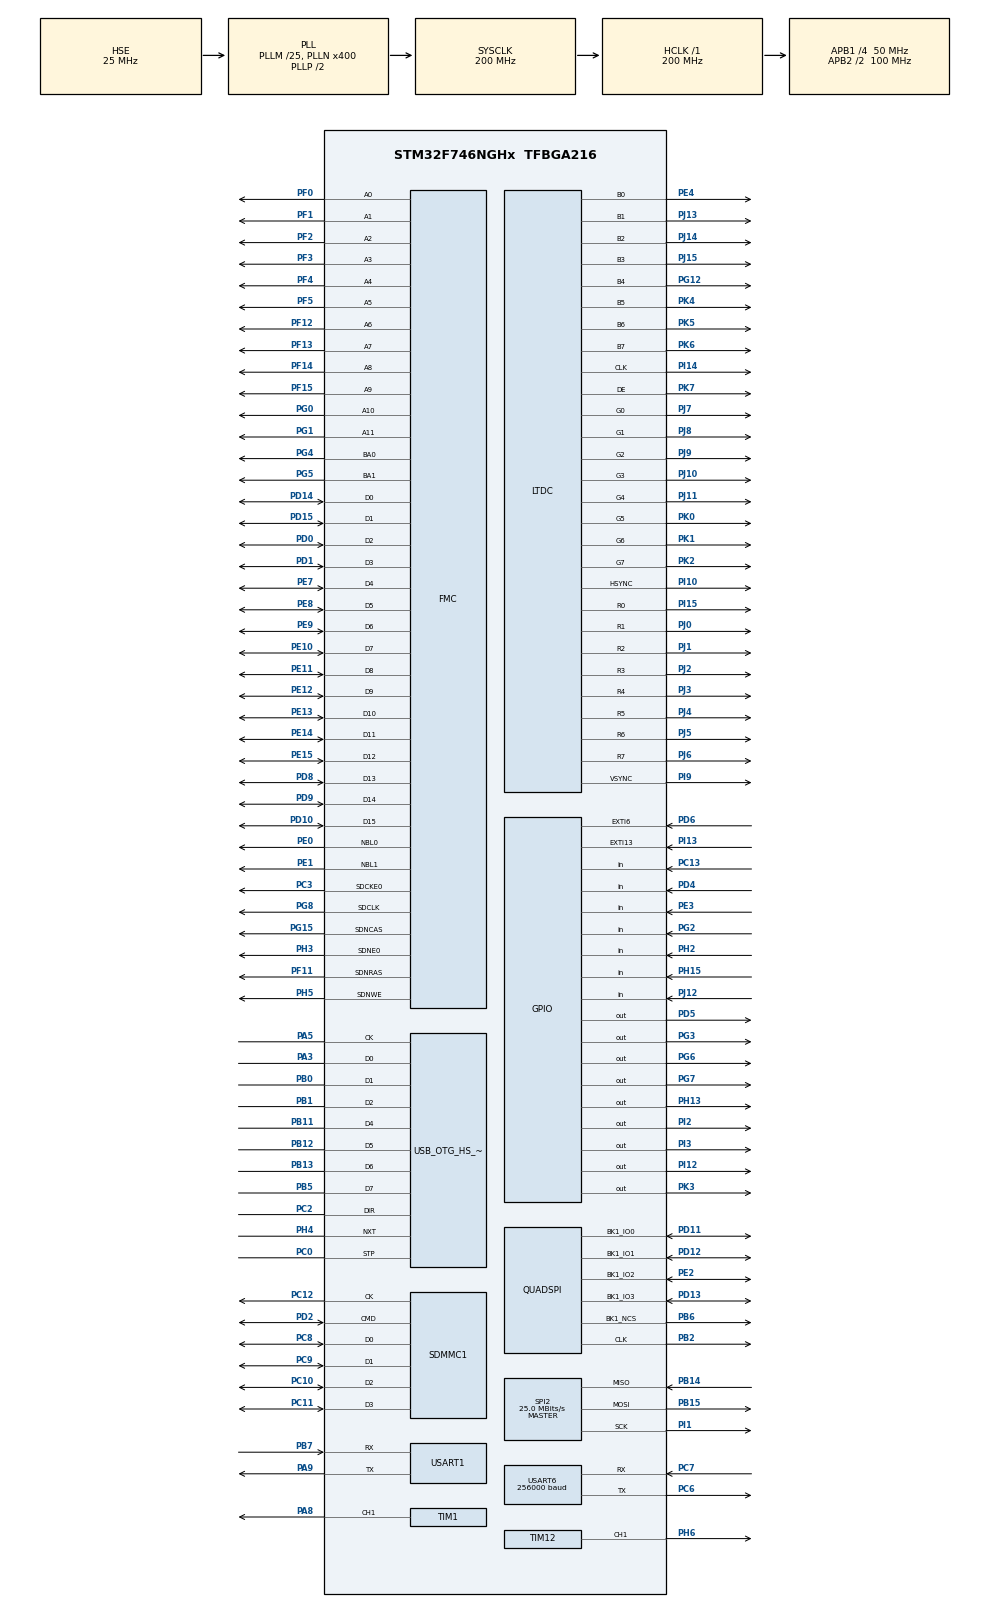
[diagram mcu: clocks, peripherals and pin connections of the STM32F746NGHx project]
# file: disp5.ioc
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Dma.MEMTOMEM.2.Direction=DMA_MEMORY_TO_MEMORY
Dma.MEMTOMEM.2.FIFOMode=DMA_FIFOMODE_ENABLE
Dma.MEMTOMEM.2.FIFOThreshold=DMA_FIFO_THRESHOLD_FULL
Dma.MEMTOMEM.2.Instance=DMA2_Stream0
Dma.MEMTOMEM.2.MemBurst=DMA_MBURST_SINGLE
Dma.MEMTOMEM.2.MemDataAlignment=DMA_MDATAALIGN_BYTE
Dma.MEMTOMEM.2.MemInc=DMA_MINC_ENABLE
Dma.MEMTOMEM.2.Mode=DMA_NORMAL
Dma.MEMTOMEM.2.PeriphBurst=DMA_PBURST_SINGLE
Dma.MEMTOMEM.2.PeriphDataAlignment=DMA_PDATAALIGN_BYTE
Dma.MEMTOMEM.2.PeriphInc=DMA_PINC_ENABLE
Dma.MEMTOMEM.2.Priority=DMA_PRIORITY_HIGH
Dma.Request0=USART6_RX
Dma.Request1=USART6_TX
Dma.Request2=MEMTOMEM
Dma.USART6_RX.0.Direction=DMA_PERIPH_TO_MEMORY
Dma.USART6_RX.0.FIFOMode=DMA_FIFOMODE_DISABLE
Dma.USART6_RX.0.Instance=DMA2_Stream1
Dma.USART6_RX.0.MemDataAlignment=DMA_MDATAALIGN_BYTE
Dma.USART6_RX.0.MemInc=DMA_MINC_ENABLE
Dma.USART6_RX.0.Mode=DMA_NORMAL
Dma.USART6_RX.0.PeriphDataAlignment=DMA_PDATAALIGN_BYTE
Dma.USART6_RX.0.PeriphInc=DMA_PINC_DISABLE
Dma.USART6_RX.0.Priority=DMA_PRIORITY_VERY_HIGH
Dma.USART6_TX.1.Direction=DMA_MEMORY_TO_PERIPH
Dma.USART6_TX.1.FIFOMode=DMA_FIFOMODE_DISABLE
Dma.USART6_TX.1.Instance=DMA2_Stream6
Dma.USART6_TX.1.MemDataAlignment=DMA_MDATAALIGN_BYTE
Dma.USART6_TX.1.MemInc=DMA_MINC_ENABLE
Dma.USART6_TX.1.Mode=DMA_NORMAL
Dma.USART6_TX.1.PeriphDataAlignment=DMA_PDATAALIGN_BYTE
Dma.USART6_TX.1.PeriphInc=DMA_PINC_DISABLE
Dma.USART6_TX.1.Priority=DMA_PRIORITY_VERY_HIGH
FMC.CASLatency1=FMC_SDRAM_CAS_LATENCY_3
FMC.ExitSelfRefreshDelay1=7
FMC.LoadToActiveDelay1=2
FMC.RCDDelay1=2
FMC.RPDelay1=2
FMC.RPDelay2=2
FMC.ReadBurst1=FMC_SDRAM_RBURST_ENABLE
FMC.ReadBurst2=FMC_SDRAM_RBURST_ENABLE
FMC.RowCycleDelay1=7
FMC.RowCycleDelay2=7
FMC.SDClockPeriod1=FMC_SDRAM_CLOCK_PERIOD_2
FMC.SDClockPeriod2=FMC_SDRAM_CLOCK_PERIOD_2
FMC.SelfRefreshTime1=4
FMC.WriteRecoveryTime1=3
LTDC.ActiveH=272
LTDC.ActiveW=480
LTDC.Alpha_L0=255
LTDC.BlendingFactor1_L0=LTDC_BLENDING_FACTOR1_CA
LTDC.BlendingFactor2_L0=LTDC_BLENDING_FACTOR2_CA
LTDC.FBStartAdress_L0=0xC0400000
LTDC.HBP=13
LTDC.HFP=32
LTDC.HSync=41
LTDC.ImageHeight_L0=272
LTDC.ImageWidth_L0=480
LTDC.Layers=1
LTDC.PixelFormat_L0=LTDC_PIXEL_FORMAT_ARGB8888
LTDC.VSync=10
LTDC.WindowX1_L0=480
LTDC.WindowY1_L0=272
Mcu.Family=STM32F7
Mcu.Name=STM32F746NGHx
Mcu.Package=TFBGA216
NVIC.DMA2D_IRQn=true\:0\:0\:false\:false\:true\:true\:true
NVIC.DMA2_Stream1_IRQn=true\:0\:0\:false\:false\:true\:false\:true
NVIC.DMA2_Stream6_IRQn=true\:0\:0\:false\:false\:true\:false\:true
NVIC.LTDC_IRQn=true\:0\:0\:false\:false\:true\:true\:true
NVIC.PriorityGroup=NVIC_PRIORITYGROUP_4
NVIC.TIM6_DAC_IRQn=true\:0\:0\:false\:false\:true\:false\:true
NVIC.TimeBase=TIM6_DAC_IRQn
NVIC.TimeBaseIP=TIM6
NVIC.USART6_IRQn=true\:0\:0\:false\:false\:true\:true\:true
PA0/WKUP.GPIO_Mode=GPIO_MODE_ANALOG
PA0/WKUP.GPIO_PuPd=GPIO_NOPULL
PA0/WKUP.Signal=ADCx_IN0
PA1.GPIO_Mode=GPIO_MODE_AF_PP
PA1.GPIO_PuPd=GPIO_NOPULL
PA1.GPIO_Speed=GPIO_SPEED_FREQ_VERY_HIGH
PA1.Signal=ETH_REF_CLK
PA10.GPIO_Mode=GPIO_MODE_AF_PP
PA10.GPIO_PuPd=GPIO_NOPULL
PA10.GPIO_Speed=GPIO_SPEED_FREQ_VERY_HIGH
PA10.Signal=USB_OTG_FS_ID
PA11.GPIO_Mode=GPIO_MODE_AF_PP
PA11.GPIO_PuPd=GPIO_NOPULL
PA11.GPIO_Speed=GPIO_SPEED_FREQ_VERY_HIGH
PA11.Signal=USB_OTG_FS_DM
PA12.GPIO_Mode=GPIO_MODE_AF_PP
PA12.GPIO_PuPd=GPIO_NOPULL
PA12.GPIO_Speed=GPIO_SPEED_FREQ_VERY_HIGH
PA12.Signal=USB_OTG_FS_DP
PA13.Mode=Serial_Wire
PA13.Signal=SYS_JTMS-SWDIO
PA14.Mode=Serial_Wire
PA14.Signal=SYS_JTCK-SWCLK
PA15.GPIO_ModeDefaultPP=GPIO_MODE_AF_PP
PA15.GPIO_PuPd=GPIO_NOPULL
PA15.GPIO_Speed=GPIO_SPEED_FREQ_LOW
PA15.Signal=S_TIM2_CH1_ETR
PA2.GPIO_Mode=GPIO_MODE_AF_PP
PA2.GPIO_PuPd=GPIO_NOPULL
PA2.GPIO_Speed=GPIO_SPEED_FREQ_VERY_HIGH
PA2.Signal=ETH_MDIO
PA3.GPIO_Mode=GPIO_MODE_AF_PP
PA3.GPIO_PuPd=GPIO_NOPULL
PA3.GPIO_Speed=GPIO_SPEED_FREQ_VERY_HIGH
PA3.Mode=Host_HS
PA3.Signal=USB_OTG_HS_ULPI_D0
PA4.GPIO_Mode=GPIO_MODE_AF_PP
PA4.GPIO_PuPd=GPIO_NOPULL
PA4.GPIO_Speed=GPIO_SPEED_FREQ_LOW
PA4.Signal=DCMI_HSYNC
PA5.GPIO_Mode=GPIO_MODE_AF_PP
PA5.GPIO_PuPd=GPIO_NOPULL
PA5.GPIO_Speed=GPIO_SPEED_FREQ_VERY_HIGH
PA5.Mode=Host_HS
PA5.Signal=USB_OTG_HS_ULPI_CK
PA6.Signal=DCMI_PIXCLK
PA7.GPIO_Mode=GPIO_MODE_AF_PP
PA7.GPIO_PuPd=GPIO_NOPULL
PA7.GPIO_Speed=GPIO_SPEED_FREQ_VERY_HIGH
PA7.Signal=ETH_CRS_DV
PA8.GPIO_ModeDefaultPP=GPIO_MODE_AF_PP
PA8.GPIO_PuPd=GPIO_NOPULL
PA8.GPIO_Speed=GPIO_SPEED_FREQ_LOW
PA8.Signal=S_TIM1_CH1
PA9.GPIO_Mode=GPIO_MODE_AF_PP
PA9.GPIO_ModeDefaultPP=GPIO_MODE_AF_PP
PA9.GPIO_PuPd=GPIO_NOPULL
PA9.GPIO_Speed=GPIO_SPEED_FREQ_VERY_HIGH
PA9.Mode=Asynchronous
PA9.Signal=USART1_TX
PB0.GPIO_Mode=GPIO_MODE_AF_PP
PB0.GPIO_PuPd=GPIO_NOPULL
PB0.GPIO_Speed=GPIO_SPEED_FREQ_VERY_HIGH
PB0.Mode=Host_HS
PB0.Signal=USB_OTG_HS_ULPI_D1
PB1.GPIO_Mode=GPIO_MODE_AF_PP
PB1.GPIO_PuPd=GPIO_NOPULL
PB1.GPIO_Speed=GPIO_SPEED_FREQ_VERY_HIGH
PB1.Mode=Host_HS
PB1.Signal=USB_OTG_HS_ULPI_D2
PB10.GPIO_Mode=GPIO_MODE_AF_PP
PB10.GPIO_PuPd=GPIO_NOPULL
PB10.GPIO_Speed=GPIO_SPEED_FREQ_VERY_HIGH
PB10.Signal=USB_OTG_HS_ULPI_D3
PB11.GPIO_Mode=GPIO_MODE_AF_PP
PB11.GPIO_PuPd=GPIO_NOPULL
PB11.GPIO_Speed=GPIO_SPEED_FREQ_VERY_HIGH
PB11.Mode=Host_HS
PB11.Signal=USB_OTG_HS_ULPI_D4
PB12.GPIO_Mode=GPIO_MODE_AF_PP
PB12.GPIO_PuPd=GPIO_NOPULL
PB12.GPIO_Speed=GPIO_SPEED_FREQ_VERY_HIGH
PB12.Mode=Host_HS
PB12.Signal=USB_OTG_HS_ULPI_D5
PB13.GPIO_Mode=GPIO_MODE_AF_PP
PB13.GPIO_PuPd=GPIO_NOPULL
PB13.GPIO_Speed=GPIO_SPEED_FREQ_VERY_HIGH
PB13.Mode=Host_HS
PB13.Signal=USB_OTG_HS_ULPI_D6
PB14.GPIO_Mode=GPIO_MODE_AF_PP
PB14.GPIO_PuPd=GPIO_NOPULL
PB14.GPIO_Speed=GPIO_SPEED_FREQ_VERY_HIGH
PB14.Mode=Full_Duplex_Master
PB14.Signal=SPI2_MISO
PB15.GPIO_Mode=GPIO_MODE_AF_PP
PB15.GPIO_PuPd=GPIO_NOPULL
PB15.GPIO_Speed=GPIO_SPEED_FREQ_VERY_HIGH
PB15.Mode=Full_Duplex_Master
PB15.Signal=SPI2_MOSI
PB2.Mode=Single Bank 1
PB2.Signal=QUADSPI_CLK
PB3.Signal=SYS_JTDO-SWO
PB4.GPIO_ModeDefaultPP=GPIO_MODE_AF_PP
PB4.GPIO_PuPd=GPIO_NOPULL
PB4.GPIO_Speed=GPIO_SPEED_FREQ_LOW
PB4.Signal=S_TIM3_CH1
PB5.GPIO_Mode=GPIO_MODE_AF_PP
PB5.GPIO_PuPd=GPIO_NOPULL
PB5.GPIO_Speed=GPIO_SPEED_FREQ_VERY_HIGH
PB5.Mode=Host_HS
PB5.Signal=USB_OTG_HS_ULPI_D7
PB6.GPIO_Mode=GPIO_MODE_AF_PP
PB6.GPIO_PuPd=GPIO_NOPULL
PB6.GPIO_Speed=GPIO_SPEED_FREQ_VERY_HIGH
PB6.Mode=Single Bank 1
PB6.Signal=QUADSPI_BK1_NCS
PB7.GPIO_Mode=GPIO_MODE_AF_PP
PB7.GPIO_ModeDefaultPP=GPIO_MODE_AF_PP
PB7.GPIO_PuPd=GPIO_NOPULL
PB7.GPIO_Speed=GPIO_SPEED_FREQ_VERY_HIGH
PB7.Mode=Asynchronous
PB7.Signal=USART1_RX
PB8.GPIO_Mode=GPIO_MODE_AF_OD
PB8.GPIO_PuPd=GPIO_NOPULL
PB8.GPIO_PuPdOD=GPIO_PULLUP
PB8.GPIO_Speed=GPIO_SPEED_FREQ_VERY_HIGH
PB8.Signal=I2C1_SCL
PB9.GPIO_Mode=GPIO_MODE_AF_OD
PB9.GPIO_PuPd=GPIO_NOPULL
PB9.GPIO_PuPdOD=GPIO_PULLUP
PB9.GPIO_Speed=GPIO_SPEED_FREQ_VERY_HIGH
PB9.Signal=I2C1_SDA
PC0.GPIO_Mode=GPIO_MODE_AF_PP
PC0.GPIO_PuPd=GPIO_NOPULL
PC0.GPIO_Speed=GPIO_SPEED_FREQ_VERY_HIGH
PC0.Mode=Host_HS
PC0.Signal=USB_OTG_HS_ULPI_STP
PC1.GPIO_Mode=GPIO_MODE_AF_PP
PC1.GPIO_PuPd=GPIO_NOPULL
PC1.GPIO_Speed=GPIO_SPEED_FREQ_VERY_HIGH
PC1.Signal=ETH_MDC
PC10.GPIO_Mode=GPIO_MODE_AF_PP
PC10.GPIO_PuPd=GPIO_NOPULL
PC10.GPIO_Speed_High_Default=GPIO_SPEED_FREQ_VERY_HIGH
PC10.Mode=SD_4_bits_Wide_bus
PC10.Signal=SDMMC1_D2
PC11.GPIO_Mode=GPIO_MODE_AF_PP
PC11.GPIO_PuPd=GPIO_NOPULL
PC11.GPIO_Speed_High_Default=GPIO_SPEED_FREQ_VERY_HIGH
PC11.Mode=SD_4_bits_Wide_bus
PC11.Signal=SDMMC1_D3
PC12.GPIO_Mode=GPIO_MODE_AF_PP
PC12.GPIO_PuPd=GPIO_NOPULL
PC12.GPIO_Speed_High_Default=GPIO_SPEED_FREQ_VERY_HIGH
PC12.Mode=SD_4_bits_Wide_bus
PC12.Signal=SDMMC1_CK
PC13.GPIO_Mode=GPIO_MODE_INPUT
PC13.GPIO_PuPd=GPIO_NOPULL
PC13.Signal=GPIO_Input
PC14/OSC32_IN.Mode=LSE-External-Oscillator
PC14/OSC32_IN.Signal=RCC_OSC32_IN
PC15/OSC32_OUT.Mode=LSE-External-Oscillator
PC15/OSC32_OUT.Signal=RCC_OSC32_OUT
PC2.GPIO_Mode=GPIO_MODE_AF_PP
PC2.GPIO_PuPd=GPIO_NOPULL
PC2.GPIO_Speed=GPIO_SPEED_FREQ_VERY_HIGH
PC2.Mode=Host_HS
PC2.Signal=USB_OTG_HS_ULPI_DIR
PC3.GPIO_Mode=GPIO_MODE_AF_PP
PC3.GPIO_PuPd=GPIO_NOPULL
PC3.GPIO_Speed_High_Default=GPIO_SPEED_FREQ_VERY_HIGH
PC3.Mode=SdramChipSelect1_1
PC3.Signal=FMC_SDCKE0
PC4.GPIO_Mode=GPIO_MODE_AF_PP
PC4.GPIO_PuPd=GPIO_NOPULL
PC4.GPIO_Speed=GPIO_SPEED_FREQ_VERY_HIGH
PC4.Signal=ETH_RXD0
PC5.GPIO_Mode=GPIO_MODE_AF_PP
PC5.GPIO_PuPd=GPIO_NOPULL
PC5.GPIO_Speed=GPIO_SPEED_FREQ_VERY_HIGH
PC5.Signal=ETH_RXD1
PC6.GPIO_ModeDefaultPP=GPIO_MODE_AF_PP
PC6.GPIO_PuPd=GPIO_NOPULL
PC6.GPIO_Speed=GPIO_SPEED_FREQ_VERY_HIGH
PC6.Mode=Asynchronous
PC6.Signal=USART6_TX
PC7.GPIO_ModeDefaultPP=GPIO_MODE_AF_PP
PC7.GPIO_PuPd=GPIO_NOPULL
PC7.GPIO_Speed=GPIO_SPEED_FREQ_VERY_HIGH
PC7.Mode=Asynchronous
PC7.Signal=USART6_RX
PC8.Mode=SD_4_bits_Wide_bus
PC8.Signal=SDMMC1_D0
PC9.Mode=SD_4_bits_Wide_bus
PC9.Signal=SDMMC1_D1
PD0.GPIO_Mode=GPIO_MODE_AF_PP
PD0.GPIO_PuPd=GPIO_NOPULL
PD0.GPIO_Speed_High_Default=GPIO_SPEED_FREQ_VERY_HIGH
PD0.Signal=FMC_D2_DA2
PD1.GPIO_Mode=GPIO_MODE_AF_PP
PD1.GPIO_PuPd=GPIO_NOPULL
PD1.GPIO_Speed_High_Default=GPIO_SPEED_FREQ_VERY_HIGH
PD1.Signal=FMC_D3_DA3
PD10.GPIO_Mode=GPIO_MODE_AF_PP
PD10.GPIO_PuPd=GPIO_NOPULL
PD10.GPIO_Speed_High_Default=GPIO_SPEED_FREQ_VERY_HIGH
PD10.Signal=FMC_D15_DA15
PD11.GPIO_Mode=GPIO_MODE_AF_PP
PD11.GPIO_PuPd=GPIO_NOPULL
PD11.GPIO_Speed=GPIO_SPEED_FREQ_VERY_HIGH
PD11.Mode=Single Bank 1
PD11.Signal=QUADSPI_BK1_IO0
PD12.GPIO_Mode=GPIO_MODE_AF_PP
PD12.GPIO_PuPd=GPIO_NOPULL
PD12.GPIO_Speed=GPIO_SPEED_FREQ_VERY_HIGH
PD12.Mode=Single Bank 1
PD12.Signal=QUADSPI_BK1_IO1
PD13.GPIO_Mode=GPIO_MODE_AF_PP
PD13.GPIO_PuPd=GPIO_NOPULL
PD13.GPIO_Speed=GPIO_SPEED_FREQ_VERY_HIGH
PD13.Mode=Single Bank 1
PD13.Signal=QUADSPI_BK1_IO3
PD14.GPIO_Mode=GPIO_MODE_AF_PP
PD14.GPIO_PuPd=GPIO_NOPULL
PD14.GPIO_Speed_High_Default=GPIO_SPEED_FREQ_VERY_HIGH
PD14.Signal=FMC_D0_DA0
PD15.GPIO_Mode=GPIO_MODE_AF_PP
PD15.GPIO_PuPd=GPIO_NOPULL
PD15.GPIO_Speed_High_Default=GPIO_SPEED_FREQ_VERY_HIGH
PD15.Signal=FMC_D1_DA1
PD2.GPIO_Mode=GPIO_MODE_AF_PP
PD2.GPIO_PuPd=GPIO_NOPULL
PD2.GPIO_Speed_High_Default=GPIO_SPEED_FREQ_VERY_HIGH
PD2.Mode=SD_4_bits_Wide_bus
PD2.Signal=SDMMC1_CMD
PD3.GPIO_Mode=GPIO_MODE_AF_PP
PD3.GPIO_PuPd=GPIO_NOPULL
PD3.GPIO_Speed=GPIO_SPEED_FREQ_LOW
PD3.Signal=DCMI_D5
PD4.GPIO_Mode=GPIO_MODE_INPUT
PD4.GPIO_PuPd=GPIO_NOPULL
PD4.Signal=GPIO_Input
PD5.GPIO_ModeDefaultOutputPP=GPIO_MODE_OUTPUT_PP
PD5.GPIO_PuPd=GPIO_NOPULL
PD5.GPIO_Speed=GPIO_SPEED_FREQ_LOW
PD5.PinState=GPIO_PIN_RESET
PD5.Signal=GPIO_Output
PD6.GPIO_ModeDefaultEXTI=GPIO_MODE_IT_RISING
PD6.GPIO_PuPd=GPIO_NOPULL
PD6.Signal=GPXTI6
PD7.GPIO_Mode=GPIO_MODE_AF_PP
PD7.GPIO_PuPd=GPIO_NOPULL
PD7.GPIO_Speed=GPIO_SPEED_FREQ_LOW
PD7.Signal=SPDIFRX_IN0
PD8.GPIO_Mode=GPIO_MODE_AF_PP
PD8.GPIO_PuPd=GPIO_NOPULL
PD8.GPIO_Speed_High_Default=GPIO_SPEED_FREQ_VERY_HIGH
PD8.Signal=FMC_D13_DA13
PD9.GPIO_Mode=GPIO_MODE_AF_PP
PD9.GPIO_PuPd=GPIO_NOPULL
PD9.GPIO_Speed_High_Default=GPIO_SPEED_FREQ_VERY_HIGH
PD9.Signal=FMC_D14_DA14
PE0.GPIO_Mode=GPIO_MODE_AF_PP
PE0.GPIO_PuPd=GPIO_NOPULL
PE0.GPIO_Speed_High_Default=GPIO_SPEED_FREQ_VERY_HIGH
PE0.Signal=FMC_NBL0
PE1.GPIO_Mode=GPIO_MODE_AF_PP
PE1.GPIO_PuPd=GPIO_NOPULL
PE1.GPIO_Speed_High_Default=GPIO_SPEED_FREQ_VERY_HIGH
PE1.Signal=FMC_NBL1
PE10.GPIO_Mode=GPIO_MODE_AF_PP
PE10.GPIO_PuPd=GPIO_NOPULL
PE10.GPIO_Speed_High_Default=GPIO_SPEED_FREQ_VERY_HIGH
PE10.Signal=FMC_D7_DA7
PE11.GPIO_Mode=GPIO_MODE_AF_PP
PE11.GPIO_PuPd=GPIO_NOPULL
PE11.GPIO_Speed_High_Default=GPIO_SPEED_FREQ_VERY_HIGH
PE11.Signal=FMC_D8_DA8
PE12.GPIO_Mode=GPIO_MODE_AF_PP
PE12.GPIO_PuPd=GPIO_NOPULL
PE12.GPIO_Speed_High_Default=GPIO_SPEED_FREQ_VERY_HIGH
PE12.Signal=FMC_D9_DA9
PE13.GPIO_Mode=GPIO_MODE_AF_PP
PE13.GPIO_PuPd=GPIO_NOPULL
PE13.GPIO_Speed_High_Default=GPIO_SPEED_FREQ_VERY_HIGH
PE13.Signal=FMC_D10_DA10
PE14.GPIO_Mode=GPIO_MODE_AF_PP
PE14.GPIO_PuPd=GPIO_NOPULL
PE14.GPIO_Speed_High_Default=GPIO_SPEED_FREQ_VERY_HIGH
PE14.Signal=FMC_D11_DA11
PE15.GPIO_Mode=GPIO_MODE_AF_PP
PE15.GPIO_PuPd=GPIO_NOPULL
PE15.GPIO_Speed_High_Default=GPIO_SPEED_FREQ_VERY_HIGH
PE15.Signal=FMC_D12_DA12
PE2.GPIO_Mode=GPIO_MODE_AF_PP
PE2.GPIO_PuPd=GPIO_NOPULL
PE2.GPIO_Speed=GPIO_SPEED_FREQ_VERY_HIGH
PE2.Mode=Single Bank 1
PE2.Signal=QUADSPI_BK1_IO2
PE3.GPIO_Mode=GPIO_MODE_INPUT
PE3.GPIO_PuPd=GPIO_NOPULL
PE3.Signal=GPIO_Input
PE4.GPIO_Mode=GPIO_MODE_AF_PP
PE4.GPIO_PuPd=GPIO_NOPULL
PE4.GPIO_Speed=GPIO_SPEED_FREQ_LOW
PE4.Mode=RGB888
PE4.Signal=LTDC_B0
PE5.GPIO_Mode=GPIO_MODE_AF_PP
PE5.GPIO_PuPd=GPIO_NOPULL
PE5.GPIO_Speed=GPIO_SPEED_FREQ_LOW
PE5.Signal=DCMI_D6
PE6.GPIO_Mode=GPIO_MODE_AF_PP
PE6.GPIO_PuPd=GPIO_NOPULL
PE6.GPIO_Speed=GPIO_SPEED_FREQ_LOW
PE6.Signal=DCMI_D7
PE7.GPIO_Mode=GPIO_MODE_AF_PP
PE7.GPIO_PuPd=GPIO_NOPULL
PE7.GPIO_Speed_High_Default=GPIO_SPEED_FREQ_VERY_HIGH
PE7.Signal=FMC_D4_DA4
PE8.GPIO_Mode=GPIO_MODE_AF_PP
PE8.GPIO_PuPd=GPIO_NOPULL
PE8.GPIO_Speed_High_Default=GPIO_SPEED_FREQ_VERY_HIGH
PE8.Signal=FMC_D5_DA5
PE9.GPIO_Mode=GPIO_MODE_AF_PP
PE9.GPIO_PuPd=GPIO_NOPULL
PE9.GPIO_Speed_High_Default=GPIO_SPEED_FREQ_VERY_HIGH
PE9.Signal=FMC_D6_DA6
PF0.GPIO_Mode=GPIO_MODE_AF_PP
PF0.GPIO_PuPd=GPIO_NOPULL
PF0.GPIO_Speed_High_Default=GPIO_SPEED_FREQ_VERY_HIGH
PF0.Signal=FMC_A0
PF1.GPIO_Mode=GPIO_MODE_AF_PP
PF1.GPIO_PuPd=GPIO_NOPULL
PF1.GPIO_Speed_High_Default=GPIO_SPEED_FREQ_VERY_HIGH
PF1.Signal=FMC_A1
PF10.GPIO_Mode=GPIO_MODE_ANALOG
PF10.GPIO_PuPd=GPIO_NOPULL
PF10.Signal=ADC3_IN8
PF11.GPIO_Mode=GPIO_MODE_AF_PP
PF11.GPIO_PuPd=GPIO_NOPULL
PF11.GPIO_Speed_High_Default=GPIO_SPEED_FREQ_VERY_HIGH
PF11.Signal=FMC_SDNRAS
PF12.GPIO_Mode=GPIO_MODE_AF_PP
PF12.GPIO_PuPd=GPIO_NOPULL
PF12.GPIO_Speed_High_Default=GPIO_SPEED_FREQ_VERY_HIGH
PF12.Signal=FMC_A6
PF13.GPIO_Mode=GPIO_MODE_AF_PP
PF13.GPIO_PuPd=GPIO_NOPULL
PF13.GPIO_Speed_High_Default=GPIO_SPEED_FREQ_VERY_HIGH
PF13.Signal=FMC_A7
PF14.GPIO_Mode=GPIO_MODE_AF_PP
PF14.GPIO_PuPd=GPIO_NOPULL
PF14.GPIO_Speed_High_Default=GPIO_SPEED_FREQ_VERY_HIGH
PF14.Signal=FMC_A8
PF15.GPIO_Mode=GPIO_MODE_AF_PP
PF15.GPIO_PuPd=GPIO_NOPULL
PF15.GPIO_Speed_High_Default=GPIO_SPEED_FREQ_VERY_HIGH
PF15.Signal=FMC_A9
PF2.GPIO_Mode=GPIO_MODE_AF_PP
PF2.GPIO_PuPd=GPIO_NOPULL
PF2.GPIO_Speed_High_Default=GPIO_SPEED_FREQ_VERY_HIGH
PF2.Signal=FMC_A2
PF3.GPIO_Mode=GPIO_MODE_AF_PP
PF3.GPIO_PuPd=GPIO_NOPULL
PF3.GPIO_Speed_High_Default=GPIO_SPEED_FREQ_VERY_HIGH
PF3.Signal=FMC_A3
PF4.GPIO_Mode=GPIO_MODE_AF_PP
PF4.GPIO_PuPd=GPIO_NOPULL
PF4.GPIO_Speed_High_Default=GPIO_SPEED_FREQ_VERY_HIGH
PF4.Signal=FMC_A4
PF5.GPIO_Mode=GPIO_MODE_AF_PP
PF5.GPIO_PuPd=GPIO_NOPULL
PF5.GPIO_Speed_High_Default=GPIO_SPEED_FREQ_VERY_HIGH
PF5.Signal=FMC_A5
PF6.GPIO_Mode=GPIO_MODE_ANALOG
PF6.GPIO_PuPd=GPIO_NOPULL
PF6.Signal=ADC3_IN4
PF7.GPIO_Mode=GPIO_MODE_ANALOG
PF7.GPIO_PuPd=GPIO_NOPULL
PF7.Signal=ADC3_IN5
PF8.GPIO_Mode=GPIO_MODE_ANALOG
PF8.GPIO_PuPd=GPIO_NOPULL
PF8.Signal=ADC3_IN6
PF9.GPIO_Mode=GPIO_MODE_ANALOG
PF9.GPIO_PuPd=GPIO_NOPULL
PF9.Signal=ADC3_IN7
PG0.GPIO_Mode=GPIO_MODE_AF_PP
PG0.GPIO_PuPd=GPIO_NOPULL
PG0.GPIO_Speed_High_Default=GPIO_SPEED_FREQ_VERY_HIGH
PG0.Signal=FMC_A10
PG1.GPIO_Mode=GPIO_MODE_AF_PP
PG1.GPIO_PuPd=GPIO_NOPULL
PG1.GPIO_Speed_High_Default=GPIO_SPEED_FREQ_VERY_HIGH
PG1.Signal=FMC_A11
PG10.GPIO_Mode=GPIO_MODE_AF_PP
PG10.GPIO_PuPd=GPIO_NOPULL
PG10.GPIO_Speed=GPIO_SPEED_FREQ_LOW
PG10.Signal=SAI2_SD_B
PG11.GPIO_Mode=GPIO_MODE_AF_PP
PG11.GPIO_PuPd=GPIO_NOPULL
PG11.GPIO_Speed=GPIO_SPEED_FREQ_VERY_HIGH
PG11.Signal=ETH_TX_EN
PG12.GPIO_Mode=GPIO_MODE_AF_PP
PG12.GPIO_PuPd=GPIO_NOPULL
PG12.GPIO_Speed=GPIO_SPEED_FREQ_LOW
PG12.Mode=RGB888
PG12.Signal=LTDC_B4
PG13.GPIO_Mode=GPIO_MODE_AF_PP
PG13.GPIO_PuPd=GPIO_NOPULL
PG13.GPIO_Speed=GPIO_SPEED_FREQ_VERY_HIGH
PG13.Signal=ETH_TXD0
PG14.GPIO_Mode=GPIO_MODE_AF_PP
PG14.GPIO_PuPd=GPIO_NOPULL
PG14.GPIO_Speed=GPIO_SPEED_FREQ_VERY_HIGH
PG14.Signal=ETH_TXD1
PG15.GPIO_Mode=GPIO_MODE_AF_PP
PG15.GPIO_PuPd=GPIO_NOPULL
PG15.GPIO_Speed_High_Default=GPIO_SPEED_FREQ_VERY_HIGH
PG15.Signal=FMC_SDNCAS
PG2.GPIO_Mode=GPIO_MODE_INPUT
PG2.GPIO_PuPd=GPIO_NOPULL
PG2.Signal=GPIO_Input
PG3.GPIO_ModeDefaultOutputPP=GPIO_MODE_OUTPUT_PP
PG3.GPIO_PuPd=GPIO_NOPULL
PG3.GPIO_Speed=GPIO_SPEED_FREQ_LOW
PG3.PinState=GPIO_PIN_RESET
PG3.Signal=GPIO_Output
PG4.GPIO_Mode=GPIO_MODE_AF_PP
PG4.GPIO_PuPd=GPIO_NOPULL
PG4.GPIO_Speed_High_Default=GPIO_SPEED_FREQ_VERY_HIGH
PG4.Signal=FMC_A14_BA0
PG5.GPIO_Mode=GPIO_MODE_AF_PP
PG5.GPIO_PuPd=GPIO_NOPULL
PG5.GPIO_Speed_High_Default=GPIO_SPEED_FREQ_VERY_HIGH
PG5.Signal=FMC_A15_BA1
PG6.GPIO_ModeDefaultOutputPP=GPIO_MODE_OUTPUT_PP
PG6.GPIO_PuPd=GPIO_NOPULL
PG6.GPIO_Speed=GPIO_SPEED_FREQ_LOW
PG6.PinState=GPIO_PIN_RESET
PG6.Signal=GPIO_Output
PG7.GPIO_ModeDefaultOutputPP=GPIO_MODE_OUTPUT_PP
PG7.GPIO_PuPd=GPIO_NOPULL
PG7.GPIO_Speed=GPIO_SPEED_FREQ_LOW
PG7.PinState=GPIO_PIN_RESET
PG7.Signal=GPIO_Output
PG8.GPIO_Mode=GPIO_MODE_AF_PP
PG8.GPIO_PuPd=GPIO_NOPULL
PG8.GPIO_Speed_High_Default=GPIO_SPEED_FREQ_VERY_HIGH
PG8.Signal=FMC_SDCLK
PG9.GPIO_Mode=GPIO_MODE_AF_PP
PG9.GPIO_PuPd=GPIO_NOPULL
PG9.GPIO_Speed=GPIO_SPEED_FREQ_LOW
PG9.Signal=DCMI_VSYNC
PH0/OSC_IN.Mode=HSE-External-Oscillator
PH0/OSC_IN.Signal=RCC_OSC_IN
PH1/OSC_OUT.Mode=HSE-External-Oscillator
PH1/OSC_OUT.Signal=RCC_OSC_OUT
PH10.GPIO_Mode=GPIO_MODE_AF_PP
PH10.GPIO_PuPd=GPIO_NOPULL
PH10.GPIO_Speed=GPIO_SPEED_FREQ_LOW
PH10.Signal=DCMI_D1
PH11.GPIO_Mode=GPIO_MODE_AF_PP
PH11.GPIO_PuPd=GPIO_NOPULL
PH11.GPIO_Speed=GPIO_SPEED_FREQ_LOW
PH11.Signal=DCMI_D2
PH12.GPIO_Mode=GPIO_MODE_AF_PP
PH12.GPIO_PuPd=GPIO_NOPULL
PH12.GPIO_Speed=GPIO_SPEED_FREQ_LOW
PH12.Signal=DCMI_D3
PH13.GPIO_ModeDefaultOutputPP=GPIO_MODE_OUTPUT_PP
PH13.GPIO_PuPd=GPIO_NOPULL
PH13.GPIO_Speed=GPIO_SPEED_FREQ_LOW
PH13.PinState=GPIO_PIN_RESET
PH13.Signal=GPIO_Output
PH14.GPIO_Mode=GPIO_MODE_AF_PP
PH14.GPIO_PuPd=GPIO_NOPULL
PH14.GPIO_Speed=GPIO_SPEED_FREQ_LOW
PH14.Signal=DCMI_D4
PH15.GPIO_Mode=GPIO_MODE_INPUT
PH15.GPIO_PuPd=GPIO_NOPULL
PH15.Signal=GPIO_Input
PH2.GPIO_Mode=GPIO_MODE_INPUT
PH2.GPIO_PuPd=GPIO_NOPULL
PH2.Signal=GPIO_Input
PH3.GPIO_Mode=GPIO_MODE_AF_PP
PH3.GPIO_PuPd=GPIO_NOPULL
PH3.GPIO_Speed_High_Default=GPIO_SPEED_FREQ_VERY_HIGH
PH3.Mode=SdramChipSelect1_1
PH3.Signal=FMC_SDNE0
PH4.GPIO_Mode=GPIO_MODE_AF_PP
PH4.GPIO_PuPd=GPIO_NOPULL
PH4.GPIO_Speed=GPIO_SPEED_FREQ_VERY_HIGH
PH4.Mode=Host_HS
PH4.Signal=USB_OTG_HS_ULPI_NXT
PH5.GPIO_Mode=GPIO_MODE_AF_PP
PH5.GPIO_PuPd=GPIO_NOPULL
PH5.GPIO_Speed_High_Default=GPIO_SPEED_FREQ_VERY_HIGH
PH5.Signal=FMC_SDNWE
PH6.GPIO_ModeDefaultPP=GPIO_MODE_AF_PP
PH6.GPIO_PuPd=GPIO_NOPULL
PH6.GPIO_Speed=GPIO_SPEED_FREQ_LOW
PH6.Signal=S_TIM12_CH1
PH7.GPIO_Mode=GPIO_MODE_AF_OD
PH7.GPIO_PuPdOD=GPIO_PULLUP
PH7.GPIO_Speed=GPIO_SPEED_FREQ_VERY_HIGH
PH7.Signal=I2C3_SCL
PH8.GPIO_Mode=GPIO_MODE_AF_OD
PH8.GPIO_PuPdOD=GPIO_PULLUP
PH8.GPIO_Speed=GPIO_SPEED_FREQ_VERY_HIGH
PH8.Signal=I2C3_SDA
PH9.GPIO_Mode=GPIO_MODE_AF_PP
PH9.GPIO_PuPd=GPIO_NOPULL
PH9.GPIO_Speed=GPIO_SPEED_FREQ_LOW
PH9.Signal=DCMI_D0
PI0.GPIO_ModeDefaultPP=GPIO_MODE_AF_PP
PI0.GPIO_PuPd=GPIO_NOPULL
PI0.GPIO_Speed=GPIO_SPEED_FREQ_LOW
PI0.Signal=S_TIM5_CH4
PI1.GPIO_Mode=GPIO_MODE_AF_PP
PI1.GPIO_PuPd=GPIO_NOPULL
PI1.GPIO_Speed=GPIO_SPEED_FREQ_VERY_HIGH
PI1.Mode=Full_Duplex_Master
PI1.Signal=SPI2_SCK
PI10.GPIO_Mode=GPIO_MODE_AF_PP
PI10.GPIO_PuPd=GPIO_NOPULL
PI10.GPIO_Speed=GPIO_SPEED_FREQ_LOW
PI10.Mode=RGB888
PI10.Signal=LTDC_HSYNC
PI12.GPIO_ModeDefaultOutputPP=GPIO_MODE_OUTPUT_PP
PI12.GPIO_PuPd=GPIO_NOPULL
PI12.GPIO_Speed=GPIO_SPEED_FREQ_LOW
PI12.PinState=GPIO_PIN_RESET
PI12.Signal=GPIO_Output
PI13.GPIO_ModeDefaultEXTI=GPIO_MODE_IT_RISING
PI13.GPIO_PuPd=GPIO_NOPULL
PI13.Signal=GPXTI13
PI14.GPIO_Mode=GPIO_MODE_AF_PP
PI14.GPIO_PuPd=GPIO_NOPULL
PI14.GPIO_Speed=GPIO_SPEED_FREQ_LOW
PI14.Mode=RGB888
PI14.Signal=LTDC_CLK
PI15.GPIO_Mode=GPIO_MODE_AF_PP
PI15.GPIO_PuPd=GPIO_NOPULL
PI15.GPIO_Speed=GPIO_SPEED_FREQ_LOW
PI15.Mode=RGB888
PI15.Signal=LTDC_R0
PI2.GPIO_ModeDefaultOutputPP=GPIO_MODE_OUTPUT_PP
PI2.GPIO_PuPd=GPIO_NOPULL
PI2.GPIO_Speed=GPIO_SPEED_FREQ_LOW
PI2.PinState=GPIO_PIN_RESET
PI2.Signal=GPIO_Output
PI3.GPIO_ModeDefaultOutputPP=GPIO_MODE_OUTPUT_PP
PI3.GPIO_PuPd=GPIO_NOPULL
PI3.GPIO_Speed=GPIO_SPEED_FREQ_LOW
PI3.PinState=GPIO_PIN_RESET
PI3.Signal=GPIO_Output
PI4.GPIO_Mode=GPIO_MODE_AF_PP
PI4.GPIO_PuPd=GPIO_NOPULL
PI4.GPIO_Speed=GPIO_SPEED_FREQ_LOW
PI4.Signal=SAI2_MCLK_A
PI5.GPIO_Mode=GPIO_MODE_AF_PP
PI5.GPIO_PuPd=GPIO_NOPULL
PI5.GPIO_Speed=GPIO_SPEED_FREQ_LOW
PI5.Signal=SAI2_SCK_A
PI6.GPIO_Mode=GPIO_MODE_AF_PP
PI6.GPIO_PuPd=GPIO_NOPULL
PI6.GPIO_Speed=GPIO_SPEED_FREQ_LOW
PI6.Signal=SAI2_SD_A
PI7.GPIO_Mode=GPIO_MODE_AF_PP
PI7.GPIO_PuPd=GPIO_NOPULL
PI7.GPIO_Speed=GPIO_SPEED_FREQ_LOW
PI7.Signal=SAI2_FS_A
PI8.Signal=RTC_TS
PI9.GPIO_Mode=GPIO_MODE_AF_PP
PI9.GPIO_PuPd=GPIO_NOPULL
PI9.GPIO_Speed=GPIO_SPEED_FREQ_LOW
PI9.Mode=RGB888
PI9.Signal=LTDC_VSYNC
PJ0.GPIO_Mode=GPIO_MODE_AF_PP
PJ0.GPIO_PuPd=GPIO_NOPULL
PJ0.GPIO_Speed=GPIO_SPEED_FREQ_LOW
PJ0.Mode=RGB888
PJ0.Signal=LTDC_R1
PJ1.GPIO_Mode=GPIO_MODE_AF_PP
PJ1.GPIO_PuPd=GPIO_NOPULL
PJ1.GPIO_Speed=GPIO_SPEED_FREQ_LOW
PJ1.Mode=RGB888
PJ1.Signal=LTDC_R2
PJ10.GPIO_Mode=GPIO_MODE_AF_PP
PJ10.GPIO_PuPd=GPIO_NOPULL
PJ10.GPIO_Speed=GPIO_SPEED_FREQ_LOW
PJ10.Mode=RGB888
PJ10.Signal=LTDC_G3
PJ11.GPIO_Mode=GPIO_MODE_AF_PP
PJ11.GPIO_PuPd=GPIO_NOPULL
PJ11.GPIO_Speed=GPIO_SPEED_FREQ_LOW
PJ11.Mode=RGB888
PJ11.Signal=LTDC_G4
PJ12.GPIO_Mode=GPIO_MODE_INPUT
PJ12.GPIO_PuPd=GPIO_NOPULL
PJ12.Signal=GPIO_Input
PJ13.GPIO_Mode=GPIO_MODE_AF_PP
PJ13.GPIO_PuPd=GPIO_NOPULL
PJ13.GPIO_Speed=GPIO_SPEED_FREQ_LOW
PJ13.Mode=RGB888
PJ13.Signal=LTDC_B1
PJ14.GPIO_Mode=GPIO_MODE_AF_PP
PJ14.GPIO_PuPd=GPIO_NOPULL
PJ14.GPIO_Speed=GPIO_SPEED_FREQ_LOW
PJ14.Mode=RGB888
PJ14.Signal=LTDC_B2
PJ15.GPIO_Mode=GPIO_MODE_AF_PP
PJ15.GPIO_PuPd=GPIO_NOPULL
PJ15.GPIO_Speed=GPIO_SPEED_FREQ_LOW
PJ15.Mode=RGB888
PJ15.Signal=LTDC_B3
PJ2.GPIO_Mode=GPIO_MODE_AF_PP
PJ2.GPIO_PuPd=GPIO_NOPULL
PJ2.GPIO_Speed=GPIO_SPEED_FREQ_LOW
PJ2.Mode=RGB888
PJ2.Signal=LTDC_R3
PJ3.GPIO_Mode=GPIO_MODE_AF_PP
PJ3.GPIO_PuPd=GPIO_NOPULL
PJ3.GPIO_Speed=GPIO_SPEED_FREQ_LOW
PJ3.Mode=RGB888
PJ3.Signal=LTDC_R4
PJ4.GPIO_Mode=GPIO_MODE_AF_PP
PJ4.GPIO_PuPd=GPIO_NOPULL
PJ4.GPIO_Speed=GPIO_SPEED_FREQ_LOW
PJ4.Mode=RGB888
PJ4.Signal=LTDC_R5
PJ5.GPIO_Mode=GPIO_MODE_AF_PP
PJ5.GPIO_PuPd=GPIO_NOPULL
PJ5.GPIO_Speed=GPIO_SPEED_FREQ_LOW
PJ5.Mode=RGB888
PJ5.Signal=LTDC_R6
PJ6.GPIO_Mode=GPIO_MODE_AF_PP
PJ6.GPIO_PuPd=GPIO_NOPULL
PJ6.GPIO_Speed=GPIO_SPEED_FREQ_LOW
PJ6.Mode=RGB888
PJ6.Signal=LTDC_R7
PJ7.GPIO_Mode=GPIO_MODE_AF_PP
PJ7.GPIO_PuPd=GPIO_NOPULL
PJ7.GPIO_Speed=GPIO_SPEED_FREQ_LOW
PJ7.Mode=RGB888
PJ7.Signal=LTDC_G0
PJ8.GPIO_Mode=GPIO_MODE_AF_PP
PJ8.GPIO_PuPd=GPIO_NOPULL
PJ8.GPIO_Speed=GPIO_SPEED_FREQ_LOW
PJ8.Mode=RGB888
PJ8.Signal=LTDC_G1
PJ9.GPIO_Mode=GPIO_MODE_AF_PP
PJ9.GPIO_PuPd=GPIO_NOPULL
PJ9.GPIO_Speed=GPIO_SPEED_FREQ_LOW
PJ9.Mode=RGB888
PJ9.Signal=LTDC_G2
PK0.GPIO_Mode=GPIO_MODE_AF_PP
PK0.GPIO_PuPd=GPIO_NOPULL
PK0.GPIO_Speed=GPIO_SPEED_FREQ_LOW
PK0.Mode=RGB888
PK0.Signal=LTDC_G5
PK1.GPIO_Mode=GPIO_MODE_AF_PP
PK1.GPIO_PuPd=GPIO_NOPULL
PK1.GPIO_Speed=GPIO_SPEED_FREQ_LOW
PK1.Mode=RGB888
PK1.Signal=LTDC_G6
PK2.GPIO_Mode=GPIO_MODE_AF_PP
PK2.GPIO_PuPd=GPIO_NOPULL
PK2.GPIO_Speed=GPIO_SPEED_FREQ_LOW
PK2.Mode=RGB888
PK2.Signal=LTDC_G7
PK3.GPIO_ModeDefaultOutputPP=GPIO_MODE_OUTPUT_PP
PK3.GPIO_PuPd=GPIO_NOPULL
PK3.GPIO_Speed=GPIO_SPEED_FREQ_LOW
PK3.PinState=GPIO_PIN_RESET
PK3.Signal=GPIO_Output
PK4.GPIO_Mode=GPIO_MODE_AF_PP
PK4.GPIO_PuPd=GPIO_NOPULL
PK4.GPIO_Speed=GPIO_SPEED_FREQ_LOW
PK4.Mode=RGB888
PK4.Signal=LTDC_B5
PK5.GPIO_Mode=GPIO_MODE_AF_PP
PK5.GPIO_PuPd=GPIO_NOPULL
PK5.GPIO_Speed=GPIO_SPEED_FREQ_LOW
PK5.Mode=RGB888
PK5.Signal=LTDC_B6
PK6.GPIO_Mode=GPIO_MODE_AF_PP
PK6.GPIO_PuPd=GPIO_NOPULL
PK6.GPIO_Speed=GPIO_SPEED_FREQ_LOW
PK6.Mode=RGB888
PK6.Signal=LTDC_B7
PK7.GPIO_Mode=GPIO_MODE_AF_PP
PK7.GPIO_PuPd=GPIO_NOPULL
PK7.GPIO_Speed=GPIO_SPEED_FREQ_LOW
PK7.Mode=RGB888
PK7.Signal=LTDC_DE
ProjectManager.HeapSize=0x200
ProjectManager.StackSize=0x400
ProjectManager.TargetToolchain=STM32CubeIDE
RCC.AHBFreq_Value=200000000
RCC.APB1CLKDivider=RCC_HCLK_DIV4
RCC.APB1Freq_Value=50000000
RCC.APB1TimFreq_Value=100000000
RCC.APB2CLKDivider=RCC_HCLK_DIV2
RCC.APB2Freq_Value=100000000
RCC.APB2TimFreq_Value=200000000
RCC.CortexFreq_Value=200000000
RCC.HCLKFreq_Value=200000000
RCC.HSE_VALUE=25000000
RCC.HSI_VALUE=16000000
RCC.PLL48CLockSelection=RCC_CLK48SOURCE_PLLSAIP
RCC.PLLI2SN=100
RCC.PLLM=25
RCC.PLLN=400
RCC.PLLQ=9
RCC.PLLSAIN=384
RCC.PLLSAIP=RCC_PLLSAIP_DIV8
RCC.PLLSAIR=5
RCC.PLLSAIRDiv=RCC_PLLSAIDIVR_8
RCC.PLLSourceVirtual=RCC_PLLSOURCE_HSE
RCC.SDMMCClockSelection=RCC_SDMMC1CLKSOURCE_CLK48
RCC.SYSCLKFreq_VALUE=200000000
RCC.SYSCLKSource=RCC_SYSCLKSOURCE_PLLCLK
RCC.USBFreq_Value=48000000
RCC.VCOOutputFreq_Value=400000000
SDMMC1.WideMode=SDMMC_BUS_WIDE_4B
SH.ADCx_IN0.0=ADC3_IN0
SH.FMC_A0.0=FMC_A0,12b-sda1
SH.FMC_A1.0=FMC_A1,12b-sda1
SH.FMC_A10.0=FMC_A10,12b-sda1
SH.FMC_A11.0=FMC_A11,12b-sda1
SH.FMC_A14_BA0.0=FMC_BA0,FourSdramBanks1
SH.FMC_A15_BA1.0=FMC_BA1,FourSdramBanks1
SH.FMC_A2.0=FMC_A2,12b-sda1
SH.FMC_A3.0=FMC_A3,12b-sda1
SH.FMC_A4.0=FMC_A4,12b-sda1
SH.FMC_A5.0=FMC_A5,12b-sda1
SH.FMC_A6.0=FMC_A6,12b-sda1
SH.FMC_A7.0=FMC_A7,12b-sda1
SH.FMC_A8.0=FMC_A8,12b-sda1
SH.FMC_A9.0=FMC_A9,12b-sda1
SH.FMC_D0_DA0.0=FMC_D0,sd-16b-d1
SH.FMC_D10_DA10.0=FMC_D10,sd-16b-d1
SH.FMC_D11_DA11.0=FMC_D11,sd-16b-d1
SH.FMC_D12_DA12.0=FMC_D12,sd-16b-d1
SH.FMC_D13_DA13.0=FMC_D13,sd-16b-d1
SH.FMC_D14_DA14.0=FMC_D14,sd-16b-d1
SH.FMC_D15_DA15.0=FMC_D15,sd-16b-d1
SH.FMC_D1_DA1.0=FMC_D1,sd-16b-d1
SH.FMC_D2_DA2.0=FMC_D2,sd-16b-d1
SH.FMC_D3_DA3.0=FMC_D3,sd-16b-d1
SH.FMC_D4_DA4.0=FMC_D4,sd-16b-d1
SH.FMC_D5_DA5.0=FMC_D5,sd-16b-d1
SH.FMC_D6_DA6.0=FMC_D6,sd-16b-d1
SH.FMC_D7_DA7.0=FMC_D7,sd-16b-d1
SH.FMC_D8_DA8.0=FMC_D8,sd-16b-d1
SH.FMC_D9_DA9.0=FMC_D9,sd-16b-d1
SH.FMC_NBL0.0=FMC_NBL0,Sd2ByteEnable1
SH.FMC_NBL1.0=FMC_NBL1,Sd2ByteEnable1
SH.FMC_SDCLK.0=FMC_SDCLK,12b-sda1
SH.FMC_SDNCAS.0=FMC_SDNCAS,12b-sda1
SH.FMC_SDNRAS.0=FMC_SDNRAS,12b-sda1
SH.FMC_SDNWE.0=FMC_SDNWE,12b-sda1
SH.S_TIM12_CH1.0=TIM12_CH1,PWM Generation1 CH1
SH.S_TIM1_CH1.0=TIM1_CH1,PWM Generation1 CH1
SH.S_TIM2_CH1_ETR.0=TIM2_CH1
SH.S_TIM3_CH1.0=TIM3_CH1
SH.S_TIM5_CH4.0=TIM5_CH4
SPI2.BaudRatePrescaler=SPI_BAUDRATEPRESCALER_2
SPI2.CalculateBaudRate=25.0 MBits/s
SPI2.Direction=SPI_DIRECTION_2LINES
SPI2.Mode=SPI_MODE_MASTER
SPI2.VirtualType=VM_MASTER
TIM1.Channel-PWM\ Generation1\ CH1=TIM_CHANNEL_1
TIM12.Channel-PWM\ Generation1\ CH1=TIM_CHANNEL_1
TIM12.Period=1000
TIM12.Prescaler=3
TIM12.Pulse-PWM\ Generation1\ CH1=500
USART1.VirtualMode-Asynchronous=VM_ASYNC
USART6.BaudRate=256000
USART6.VirtualMode-Asynchronous=VM_ASYNC
VP_CRC_VS_CRC.Mode=CRC_Activate
VP_DMA2D_VS_DMA2D.Mode=DMA2D_Activate
VP_SYS_VS_tim6.Mode=TIM6
VP_TIM1_VS_ClockSourceINT.Mode=Internal
VP_TIM2_VS_ClockSourceINT.Mode=Internal
VP_TIM3_VS_ClockSourceINT.Mode=Internal
VP_TIM5_VS_ClockSourceINT.Mode=Internal
VP_TIM8_VS_ClockSourceINT.Mode=Internal
board=STM32F746G-DISCO

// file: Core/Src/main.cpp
/* USER CODE BEGIN Header */
/**
  ******************************************************************************
  * @file           : main.c
  * @brief          : Main program body
  ******************************************************************************
  * @attention
  *
  * <h2><center>&copy; Copyright (c) 2020 STMicroelectronics.
  * All rights reserved.</center></h2>
  *
  * This software component is licensed by ST under BSD 3-Clause license,
  * the "License"; You may not use this file except in compliance with the
  * License. You may obtain a copy of the License at:
  *                        opensource.org/licenses/BSD-3-Clause
  *
  *
  */
/* USER CODE END Header */
#include "main.h"
#include "crc.h"
#include "dma.h"
#include "dma2d.h"
#include "ltdc.h"
#include "quadspi.h"
#include "sdmmc.h"
#include "spi.h"
#include "tim.h"
#include "usart.h"
#include "gpio.h"
#include "fmc.h"

/* USER CODE BEGIN Includes */

#include "stm32746g_discovery.h"
#include "stm32746g_discovery_lcd.h"
#include "lidar_driver.h"
#include "lidar.h"

/* USER CODE END Includes */

/* USER CODE BEGIN PV */
volatile bool received_flag = false;
volatile bool parseData = false;
uint8_t buff[3*BLOCK_SIZE] = {0};
lidar_map map;
/* USER CODE END PV */

void SystemClock_Config(void);
/* USER CODE BEGIN PFP */

//DMA data-packet interrupt
void HAL_UART_RxCpltCallback(UART_HandleTypeDef *huart)
{

	static uint8_t k = 0;
	static uint8_t previous_k = 2;
	static uint8_t next_k = 1;

	if(parseData)
	{
		//Set up DMA to receive next packet.
		HAL_UART_Receive_DMA(&huart6, buff + next_k * BLOCK_SIZE, BLOCK_SIZE);

		//Calculate start angles of current and last packet, compare them -> calculate step, convert to Q16
		int current_start_angle_q8 = (((uint16_t)(*(buff + k * BLOCK_SIZE + ANGLE_OFFSET_14_8)) & 0x7f) << 10);
		current_start_angle_q8 |= (*(buff + k * BLOCK_SIZE + ANGLE_OFFSET_07_0)) << 2;
		int previous_start_angle_q8 = (((uint16_t)(*(buff + previous_k * BLOCK_SIZE + ANGLE_OFFSET_14_8)) & 0x7f) << 10);
		previous_start_angle_q8 |= (*(buff + previous_k * BLOCK_SIZE + ANGLE_OFFSET_07_0)) << 2;

		int start_angle_diff_q8 = current_start_angle_q8 - previous_start_angle_q8;
		if(previous_start_angle_q8 > current_start_angle_q8) start_angle_diff_q8 += (360 << 8);
		int angle_step_q16 = (start_angle_diff_q8 << 3) / 3;
		int current_raw_angle_q16 = (previous_start_angle_q8 << 8);

		if(previous_start_angle_q8 > 0 &&  map.recv_status != RECV_STATUS_SYNCED_TWICE_MAP_READY)
		{
			for(uint8_t i = 0; i < ULTRA_CABINS_IN_RESPONSE ; i++)
			{
				//Each ultra_cabin consists of data for three points.
				int dist_q2[3];
				int angle_q6[3];
				int syncBit[3];

				//Get one ultra-cabin FROM PREVIOUS BUFFER and save it as uint32_t
				uint32_t combined = (*((uint32_t*)(buff + previous_k * BLOCK_SIZE + ULTRA_CABIN_0_OFFSET + CABIN_SIZE * i)));

				//"Magic shift", 'DO NOT TOUCH', from SDK.
				int dist_major = (combined & 0xfff);
				int dist_predict1 = (((int)(combined << 10)) >> 22);
				int dist_predict2 = (((int)combined) >> 22);

				int dist_major2;
				uint32_t scale1, scale2;

				//Fetch data from next ultra_cabin, from the right packet.
				if(i == ULTRA_CABINS_IN_RESPONSE - 1){
					//last ultra cabin in packet, get data from first ultra_cabin in "current" buffer
					dist_major2 = (*((uint32_t*)(buff + k * BLOCK_SIZE + ULTRA_CABIN_0_OFFSET + CABIN_SIZE * 0))) & 0xfff;
				}else{
					dist_major2 = (*((uint32_t*)(buff + previous_k * BLOCK_SIZE + ULTRA_CABIN_0_OFFSET + CABIN_SIZE * (i + 1)))) & 0xfff;
				}

				//### SDK MATH ###
				dist_major = _varbitscale_decode(dist_major, scale1);
				dist_major2 = _varbitscale_decode(dist_major2, scale2);

				int dist_base1 = dist_major;
				int dist_base2 = dist_major2;

				if((!dist_major) && dist_major2){
					dist_base1 = dist_major2;
					scale1 = scale2;
				}

				//Fetch data for THREE points
				dist_q2[0] = (dist_major << 2);

				//For -Wsign-compare warnings: The following line was copied from SDK and probably should not be changed
				if((dist_predict1 == 0xFFFFFE00) || (dist_predict1 == 0x1FF)){
					dist_q2[1] = 0;
				} else {
					dist_predict1 = (dist_predict1 << scale1);
					dist_q2[1] = (dist_predict1 + dist_base1) << 2;
				}

				//For -Wsign-compare warnings: The following line was copied from SDK and probably should not be changed
				if((dist_predict1 == 0xFFFFFE00) || (dist_predict2 == 0x1FF)){
					dist_q2[2] = 0;
				} else {
					dist_predict2 =  (dist_predict2 << scale2);
					dist_q2[2] = (dist_predict2 + dist_base2) << 2;
				}

				//## ENDOF SDK MATH ###
				for(int j = 0; j < 3; j++)
				{

					syncBit[j] = (((current_raw_angle_q16 + angle_step_q16) % (360 << 16)) < angle_step_q16) ? 1 : 0;

					//Check if a full 360 map is already saved (two syncs <=> twice passed 0 angle)
					if(syncBit[j]){
						if(map.recv_status == RECV_STATUS_NOT_SYNCED){
							map.recv_status = RECV_STATUS_SYNCED_ONCE;

						}else if(map.recv_status == RECV_STATUS_SYNCED_ONCE){
							map.recv_status = RECV_STATUS_SYNCED_TWICE_MAP_READY;
							break;
						}
					}

					//### SDK MATH ###
					int offset_angle_mean_q16 = (int)(7.5 * 3.1415926535 * (1<<16) / 180.0);

					if(dist_q2[j] >= (50*4)){
						const int k1 = 98361;
						const int k2 = (int)(k1/dist_q2[j]);
						offset_angle_mean_q16 = (int)((8 * 3.1415926535 * (1<<16) / 180) - (k2 << 6) - (k2 * k2 * k2) / 98304);
					}

					angle_q6[j] = ((current_raw_angle_q16 - int(offset_angle_mean_q16 * 180 / 3.14159265)) >> 10);
					current_raw_angle_q16 += angle_step_q16;

					if(angle_q6[j] < 0) angle_q6[j] += (360 << 6);
					else if(angle_q6[j] >= (360 << 6)) angle_q6[j] -= (360 << 6);

					//### ENDOF SDK MATH ###

					float f_angle = ((float) angle_q6[j])/ 64.0f;
					float f_distance = ((float) dist_q2[j]) / 4.0f;

					uint16_t quality = dist_q2[j] ? (0x2f << RPLIDAR_RESP_MEASUREMENT_QUALITY_SHIFT) : 0;

					if(f_angle >1.0 && f_angle < 360.0 && quality != 0  && map.cnt < POINTS  && map.recv_status == RECV_STATUS_SYNCED_ONCE)
					{

					  f_angle = 180.0 - f_angle;
					  if(f_angle < 0) f_angle += 360.0;

					  //Add received data to the arrays
					  map.angles[map.cnt] = f_angle;
					  map.distances[map.cnt] = f_distance;

					  //If this is the greatest distance, save it
					  if(f_distance > map.dmax){
						  map.dmax = f_distance;
						  map.amax = f_angle;
					  }
					  else if(f_distance < map.dmin && f_distance > 0.0){
						  map.dmin = f_distance;
						  map.amin = f_angle;
					  }
					  map.cnt++;
					}
				}
				if(map.recv_status == RECV_STATUS_SYNCED_TWICE_MAP_READY) break;
			}
		}
		k++;
		previous_k++;
		next_k++;
		if(k >= 3) k = 0;
		if(previous_k >= 3) previous_k = 0;
		if(next_k >= 3) next_k = 0;
	}
	//In main, this flag is used only once.
	//Can be used to indicate that DMA has finished receiving data.
	received_flag = true;
}

/* USER CODE END PFP */

int main(void)
{

  /* MCU Configuration--------------------------------------------------------*/

  /* Reset of all peripherals, Initializes the Flash interface and the Systick. */
  HAL_Init();

  /* Configure the system clock */
  SystemClock_Config();

  /* Initialize all configured peripherals */
  MX_GPIO_Init();
  MX_DMA_Init();
  MX_CRC_Init();
  MX_DMA2D_Init();
  MX_FMC_Init();
  MX_LTDC_Init();
  MX_QUADSPI_Init();
  MX_SDMMC1_SD_Init();
  MX_SPI2_Init();
  MX_TIM1_Init();
  MX_TIM2_Init();
  MX_TIM3_Init();
  MX_TIM5_Init();
  MX_TIM8_Init();
  MX_TIM12_Init();
  MX_USART1_UART_Init();
  MX_USART6_UART_Init();
  /* USER CODE BEGIN 2 */

  //Initialize LCD layers (in separate 4MB memory sectors)
  BSP_LCD_Init();
  BSP_LCD_LayerDefaultInit(0, LCD_FB_START_ADDRESS);
  BSP_LCD_LayerDefaultInit(1, LCD_FB_START_ADDRESS + 1024 * 1024 * 4);
  BSP_LCD_DisplayOn();
  BSP_LCD_SelectLayer(0);

  //Pulse 500, Period 1000. Duty 50% by default
  HAL_TIM_PWM_Start(&htim12, TIM_CHANNEL_1);

  //DMA transmits 2-byte RESET command over UART6
  HAL_UART_Transmit_DMA(&huart6, (uint8_t*) rplidar_reset, 2);

  //Clear both layers and wait  for the LIDAR to boot
  BSP_LCD_SelectLayer(0);
  BSP_LCD_Clear(0);
  BSP_LCD_SelectLayer(1);
  BSP_LCD_Clear(0);
  HAL_Delay(1200);

  //Send the ultra capsuled mode scan request over DMA
  HAL_UART_Transmit_DMA(&huart6, (uint8_t*) rplidar_scan_ultra, 9);

  //Clear UART receiving flags
  __HAL_UART_CLEAR_IT(&huart6, UART_CLEAR_NEF|UART_CLEAR_OREF);

  //Set DMA to receive 8-byte response descriptor, do parse it(parseData==false)
  HAL_UART_Receive_DMA(&huart6, buff, 8);

  //Wait until the descriptor is received.
  while(!received_flag);

  //With parseData flag on, the DMA "received" interrupt from now will now parse the data packets
  //received. The interrupt will also set DMA to pend for another 132b block, continuously.
  parseData = true;

  //Let the DMA receive blocks continuously
  HAL_UART_Receive_DMA(&huart6, buff, BLOCK_SIZE);

  //LCD layer identifier
  uint8_t k = 1;

  /* USER CODE END 2 */

  /* Infinite loop */
  /* USER CODE BEGIN WHILE */
	while(1)
	{
		k^=1; //Swap layers. Visible layer: k^1. Edited layer: k;

		//Wait for data to be gathered...

		BSP_LCD_SetLayerVisible((k^1), ENABLE);
		HAL_Delay(5); //Reduces flickering due to layer swap
		BSP_LCD_SetLayerVisible((k), DISABLE);
		BSP_LCD_SelectLayer(k);
		BSP_LCD_Clear(k);
		draw_grid(COLOR_GRID);
		draw_point(ORIGIN_X, ORIGIN_Y, make_color(255, 255, 255), 1.0);
		while(map.recv_status != RECV_STATUS_SYNCED_TWICE_MAP_READY);
		draw_connected_cloud_from_map(map, 0, 0, 1.0, true);

		//Clear received data.
		map = lidar_map();

    /* USER CODE END WHILE */

  }
}

void SystemClock_Config(void)
{
  RCC_OscInitTypeDef RCC_OscInitStruct = {0};
  RCC_ClkInitTypeDef RCC_ClkInitStruct = {0};
  RCC_PeriphCLKInitTypeDef PeriphClkInitStruct = {0};

  /** Configure LSE Drive Capability
  */
  HAL_PWR_EnableBkUpAccess();
  /** Configure the main internal regulator output voltage
  */
  __HAL_RCC_PWR_CLK_ENABLE();
  __HAL_PWR_VOLTAGESCALING_CONFIG(PWR_REGULATOR_VOLTAGE_SCALE1);
  /** Initializes the RCC Oscillators according to the specified parameters
  * in the RCC_OscInitTypeDef structure.
  */
  RCC_OscInitStruct.OscillatorType = RCC_OSCILLATORTYPE_HSE;
  RCC_OscInitStruct.HSEState = RCC_HSE_ON;
  RCC_OscInitStruct.PLL.PLLState = RCC_PLL_ON;
  RCC_OscInitStruct.PLL.PLLSource = RCC_PLLSOURCE_HSE;
  RCC_OscInitStruct.PLL.PLLM = 25;
  RCC_OscInitStruct.PLL.PLLN = 400;
  RCC_OscInitStruct.PLL.PLLP = RCC_PLLP_DIV2;
  RCC_OscInitStruct.PLL.PLLQ = 9;
  if (HAL_RCC_OscConfig(&RCC_OscInitStruct) != HAL_OK)
  {
    Error_Handler();
  }
  /** Activate the Over-Drive mode
  */
  if (HAL_PWREx_EnableOverDrive() != HAL_OK)
  {
    Error_Handler();
  }
  /** Initializes the CPU, AHB and APB buses clocks
  */
  RCC_ClkInitStruct.ClockType = RCC_CLOCKTYPE_HCLK|RCC_CLOCKTYPE_SYSCLK
                              |RCC_CLOCKTYPE_PCLK1|RCC_CLOCKTYPE_PCLK2;
  RCC_ClkInitStruct.SYSCLKSource = RCC_SYSCLKSOURCE_PLLCLK;
  RCC_ClkInitStruct.AHBCLKDivider = RCC_SYSCLK_DIV1;
  RCC_ClkInitStruct.APB1CLKDivider = RCC_HCLK_DIV4;
  RCC_ClkInitStruct.APB2CLKDivider = RCC_HCLK_DIV2;

  if (HAL_RCC_ClockConfig(&RCC_ClkInitStruct, FLASH_LATENCY_6) != HAL_OK)
  {
    Error_Handler();
  }
  PeriphClkInitStruct.PeriphClockSelection = RCC_PERIPHCLK_LTDC|RCC_PERIPHCLK_USART1
                              |RCC_PERIPHCLK_USART6|RCC_PERIPHCLK_SDMMC1
                              |RCC_PERIPHCLK_CLK48;
  PeriphClkInitStruct.PLLSAI.PLLSAIN = 384;
  PeriphClkInitStruct.PLLSAI.PLLSAIR = 5;
  PeriphClkInitStruct.PLLSAI.PLLSAIQ = 2;
  PeriphClkInitStruct.PLLSAI.PLLSAIP = RCC_PLLSAIP_DIV8;
  PeriphClkInitStruct.PLLSAIDivQ = 1;
  PeriphClkInitStruct.PLLSAIDivR = RCC_PLLSAIDIVR_8;
  PeriphClkInitStruct.Usart1ClockSelection = RCC_USART1CLKSOURCE_PCLK2;
  PeriphClkInitStruct.Usart6ClockSelection = RCC_USART6CLKSOURCE_PCLK2;
  PeriphClkInitStruct.Clk48ClockSelection = RCC_CLK48SOURCE_PLLSAIP;
  PeriphClkInitStruct.Sdmmc1ClockSelection = RCC_SDMMC1CLKSOURCE_CLK48;
  if (HAL_RCCEx_PeriphCLKConfig(&PeriphClkInitStruct) != HAL_OK)
  {
    Error_Handler();
  }
}

void HAL_TIM_PeriodElapsedCallback(TIM_HandleTypeDef *htim)
{
  if (htim->Instance == TIM6) {
    HAL_IncTick();
  }
}

void Error_Handler(void)
{
}

/************************ (C) COPYRIGHT STMicroelectronics *****END OF FILE****/
